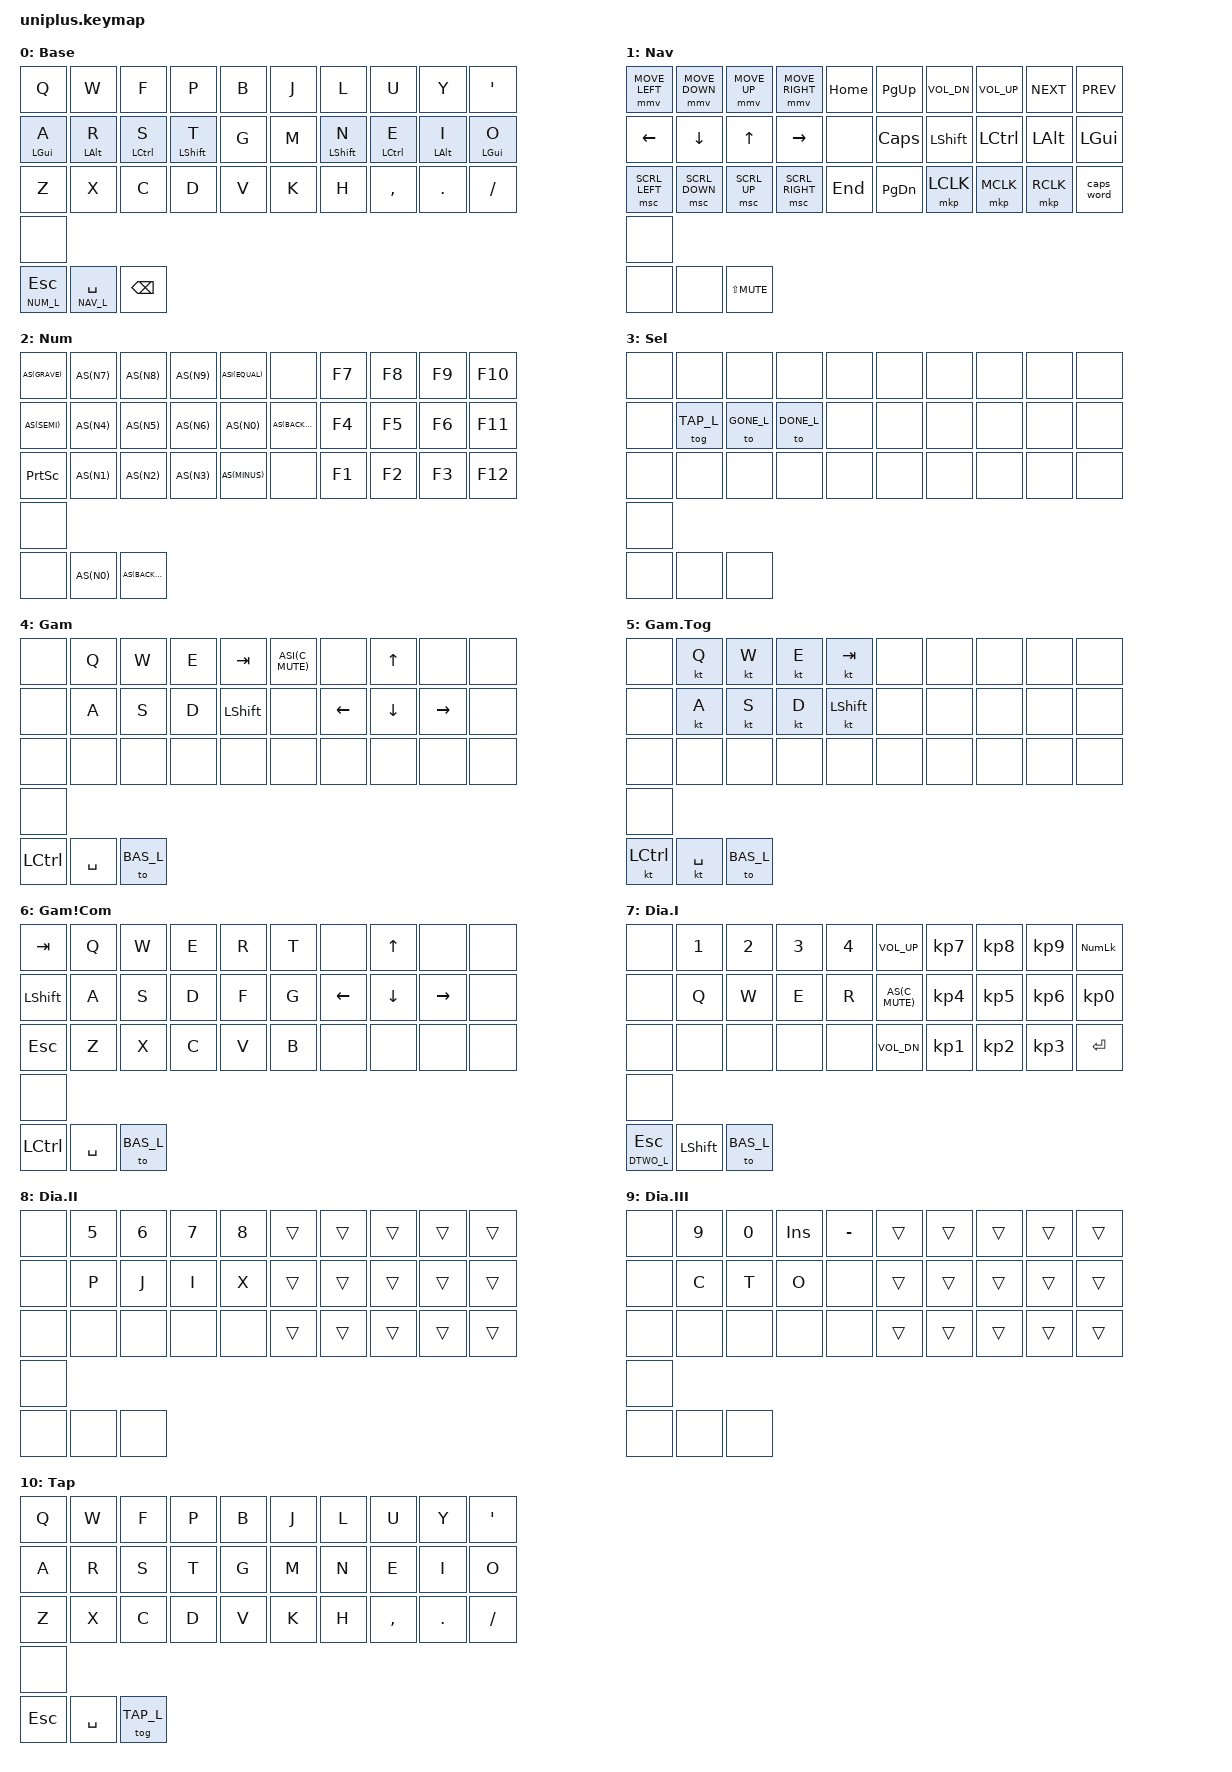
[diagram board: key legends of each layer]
/*
 * Copyright (c) 2024 Rooks
 *
 * SPDX-License-Identifier: MIT
 */

#include <behaviors.dtsi>
#include <dt-bindings/zmk/keys.h>
#include <dt-bindings/zmk/pointing.h>

// Autoshift Macro and Inversion
#define AS(keycode)  &as LS(keycode) keycode
#define ASI(keycode) &as keycode LS(keycode)

#define  BAS_L 0
#define  NAV_L 1
#define  NUM_L 2
#define  SEL_L 3
#define GONE_L 4
#define GTOG_L 5
#define GTWO_L 6
#define DONE_L 7
#define DTWO_L 8
#define DTHR_L 9
#define  TAP_L 10

/*
 *  0  1  2  3  4   5  6  7  8   9
 * 10 11 12 13 14  15 16 17 18  19
 * 20 21 22 23 24  25 26 27 28  29
 *       30 31 32  33
 */

#define KEYS_L  0  1  2  3  4   10 11 12 13 14  20 21 22 23 24
#define KEYS_R  5  6  7  8  9   15 16 17 18 19  25 26 27 28 29

#define THUMBS 30 31 32 33

// Using layer taps on thumbs, having quick tap as well helps w/ repeating space/backspace
&lt { quick-tap-ms = <200>; };

/ {
    behaviors {
        hml: hrm_left {
            compatible = "zmk,behavior-hold-tap";
            #binding-cells = <2>;
            bindings = <&kp>, <&kp>;
            flavor = "balanced";
            tapping-term-ms = <200>;
            quick-tap-ms = <150>;
            hold-trigger-key-positions = <KEYS_R THUMBS>;
            hold-trigger-on-release;
        };
        hmr: hrm_right {
            compatible = "zmk,behavior-hold-tap";
            #binding-cells = <2>;
            bindings = <&kp>, <&kp>;
            flavor = "balanced";
            tapping-term-ms = <200>;
            quick-tap-ms = <150>;
            hold-trigger-key-positions = <KEYS_L THUMBS>;
            hold-trigger-on-release;
        };
        as: auto_shift {
            compatible = "zmk,behavior-hold-tap";
            #binding-cells = <2>;
            bindings = <&kp>, <&kp>;
            flavor = "tap-preferred";
            tapping-term-ms = <200>;
            quick-tap-ms = <100>;
        };
        ght: game_hold_tap {
            compatible = "zmk,behavior-hold-tap";
            #binding-cells = <2>;
            bindings = <&kp>, <&kp>;
            flavor = "hold-preferred";
            tapping-term-ms = <150>;
        };
        glt: game_layer_tap {
            compatible = "zmk,behavior-hold-tap";
            #binding-cells = <2>;
            bindings = <&mo>, <&kp>;
            flavor = "hold-preferred";
            tapping-term-ms = <150>;
        };
    /*  Didn't work
        kt_on: key_toggle_on {
            compatible = "zmk,behavior-key-toggle";
            #binding-cells = <1>;
            display-name = "Key On";
            toggle-mode = "on";
        };
        kt_off: key_toggle_off {
            compatible = "zmk,behavior-key-toggle";
            #binding-cells = <1>;
            display-name = "Key Off";
            toggle-mode = "off";
        };
    */
    };

    keymap {
        compatible = "zmk,keymap";

        base_layer {
            display-name = "Base";
            bindings = <
                &kp Q       &kp W       &kp F        &kp P        &kp B    &kp J  &kp L        &kp U        &kp Y       &kp QUOT
                &hml LGUI A &hml LALT R &hml LCTRL S &hml LSHFT T &kp G    &kp M  &hmr LSHFT N &hmr LCTRL E &hmr LALT I &hmr LGUI O
                &kp Z       &kp X       &kp C        &kp D        &kp V    &kp K  &kp H        &kp COMMA    &kp DOT     &kp FSLH
                &none
                &lt NUM_L ESC &lt NAV_L SPACE &kp BKSP
                >;
            sensor-bindings = <&inc_dec_kp C_VOL_UP C_VOL_DN>;
        };

        navigate_layer {
            display-name = "Nav";
            bindings = <
                &mmv MOVE_LEFT &mmv MOVE_DOWN &mmv MOVE_UP &mmv MOVE_RIGHT &kp HOME    &kp PG_UP &kp C_VOL_DN &kp C_VOL_UP &kp C_NEXT &kp C_PREV
                &kp  LEFT      &kp  DOWN      &kp  UP      &kp  RIGHT      &none       &kp CAPS  &kp LSHFT    &kp LCTRL    &kp LALT   &kp LGUI
                &msc SCRL_LEFT &msc SCRL_DOWN &msc SCRL_UP &msc SCRL_RIGHT &kp END     &kp PG_DN &mkp LCLK    &mkp MCLK    &mkp RCLK  &caps_word
                &none
                &none &none &kp LS(C_MUTE)
                >;
            sensor-bindings = <&inc_dec_kp C_VOL_UP C_VOL_DN>;
        };

        number_layer {
            display-name = "Num";
            bindings = <
                AS(GRAVE) AS(N7) AS(N8) AS(N9) ASI(EQUAL)    &none         &kp F7 &kp F8 &kp F9 &kp F10
                AS(SEMI)  AS(N4) AS(N5) AS(N6) AS(N0)        AS(BACKSLASH) &kp F4 &kp F5 &kp F6 &kp F11
                &kp PSCRN AS(N1) AS(N2) AS(N3) AS(MINUS)     &none         &kp F1 &kp F2 &kp F3 &kp F12
                &none
                &none AS(N0) AS(BACKSLASH)
                >;
            sensor-bindings = <&inc_dec_kp C_VOL_UP C_VOL_DN>;
        };

        layer_selection_layer {
            display-name = "Sel";
            bindings = <
                &none &none      &none      &none      &none     &none &none &none &none &none
                &none &tog TAP_L &to GONE_L &to DONE_L &none     &none &none &none &none &none
                &none &none      &none      &none      &none     &none &none &none &none &none
                &none
                &none &none &none
                >;
            sensor-bindings = <&inc_dec_kp C_VOL_UP C_VOL_DN>;
        };

        gaming_layer {
            display-name = "Gam";
            bindings = <
                &none &kp Q &kp W &kp E &kp TAB      ASI(C_MUTE) &none    &kp UP   &none     &none
                &none &kp A &kp S &kp D &kp LSHFT    &none       &kp LEFT &kp DOWN &kp RIGHT &none
                &none &none &none &none &none        &none       &none    &none    &none     &none
                &none
                &kp LCTL  &kp SPACE &to BAS_L
                >;
            sensor-bindings = <&inc_dec_kp C_VOL_UP C_VOL_DN>;
        };

        gaming_toggles_layer {
            display-name = "Gam.Tog";
            bindings = <
                &none &kt Q &kt W &kt E &kt TAB      &none &none &none &none &none
                &none &kt A &kt S &kt D &kt LSHFT    &none &none &none &none &none
                &none &none &none &none &none        &none &none &none &none &none
                &none
                &kt LCTL  &kt SPACE &to BAS_L
                >;
            sensor-bindings = <&inc_dec_kp C_VOL_UP C_VOL_DN>;
        };

        gaming_noncomb_layer {
            display-name = "Gam!Com";
            bindings = <
                &kp TAB    &kp Q &kp W &kp E &kp R    &kp T &none    &kp UP   &none     &none
                &kp LSHIFT &kp A &kp S &kp D &kp F    &kp G &kp LEFT &kp DOWN &kp RIGHT &none
                &kp ESC    &kp Z &kp X &kp C &kp V    &kp B &none    &none    &none     &none
                &none
                &kp LCTL &kp SPACE &to BAS_L
                >;
        };

        diablo_layer {
            display-name = "Dia.I";
            bindings = <
                &none &kp N1 &kp N2 &kp N3 &kp N4    &kp C_VOL_UP &kp KP_N7 &kp KP_N8 &kp KP_N9 &kp KP_NUM
                &none &kp Q  &kp W  &kp E  &kp R      AS(C_MUTE)  &kp KP_N4 &kp KP_N5 &kp KP_N6 &kp KP_N0
                &none &none  &none  &none  &none     &kp C_VOL_DN &kp KP_N1 &kp KP_N2 &kp KP_N3 &kp RET
                &none
                &lt DTWO_L ESC &kp LSHFT &to BAS_L
                >;
            sensor-bindings = <&inc_dec_kp C_VOL_UP C_VOL_DN>;
            // IWC
        };

        diablo_two_layer {
            display-name = "Dia.II";
            bindings = <
                &none &kp N5 &kp N6 &kp N7 &kp N8    &trans &trans &trans &trans &trans
                &none &kp P  &kp J  &kp I  &kp X     &trans &trans &trans &trans &trans
                &none &none  &none  &none  &none     &trans &trans &trans &trans &trans
                &none
                &none &none &none
                >;
            sensor-bindings = <&inc_dec_kp C_VOL_UP C_VOL_DN>;
        };

        diablo_three_layer {
            display-name = "Dia.III";
            bindings = <
                &none &kp N9 &kp N0 &kp INS &kp MINUS    &trans &trans &trans &trans &trans
                &none &kp C  &kp T  &kp O   &none        &trans &trans &trans &trans &trans
                &none &none  &none  &none   &none        &trans &trans &trans &trans &trans
                &none
                &none &none &none
                >;
            sensor-bindings = <&inc_dec_kp C_VOL_UP C_VOL_DN>;
        };

        tap_layer {
            display-name = "Tap";
            bindings = <
                &kp Q &kp W &kp F &kp P &kp B    &kp J &kp L &kp U     &kp Y   &kp QUOT
                &kp A &kp R &kp S &kp T &kp G    &kp M &kp N &kp E     &kp I   &kp O
                &kp Z &kp X &kp C &kp D &kp V    &kp K &kp H &kp COMMA &kp DOT &kp FSLH
                &none
                &kp ESC &kp SPACE &tog TAP_L
                >;
            sensor-bindings = <&inc_dec_kp C_VOL_UP C_VOL_DN>;
        };

    };

    /*  Didn't work
    macros {
        fkp: force_key_press {
            compatible = "zmk,behavior-macro-one-param";
            #binding-cells = <1>;
            bindings
                = <&macro_param_1to1>
                , <&macro_press &kp  MACRO_PLACEHOLDER>
                , <&macro_pause_for_release>
                , <&macro_param_1to1>
                , <&macro_release &kp MACRO_PLACEHOLDER>;
        };
        tap_longer: tap_longer {
            compatible = "zmk,behavior-macro-one-param";
            #binding-cells = <1>;
            bindings
                = <&macro_param_1to1>
                , <&macro_tap &kp MACRO_PLACEHOLDER>;
        };
    };
    */

    combos {
        compatible = "zmk,combos";
        combo_boot       { timeout-ms = <50>; key-positions = <0 9 20 29>; bindings = <&bootloader>; };

        combo_ret        { timeout-ms = <50>; key-positions = <25 33>; bindings = <&kp RET>;    layers = <BAS_L>;  };
        combo_del        { timeout-ms = <50>; key-positions = <16 18>; bindings = <&kp DEL>;    layers = <BAS_L>;  };
        combo_tab        { timeout-ms = <50>; key-positions = <11 13>; bindings = <&kp TAB>;    layers = <BAS_L>;  };

        combo_angle_l    { timeout-ms = <50>; key-positions = <10 20>; bindings = <&kp LT>;     layers = <BAS_L>;  };
        combo_brace_l    { timeout-ms = <50>; key-positions = <11 21>; bindings = <&kp LBRC>;   layers = <BAS_L>;  };
        combo_bracket_l  { timeout-ms = <50>; key-positions = <12 22>; bindings = <&kp LBKT>;   layers = <BAS_L>;  };
        combo_paren_l    { timeout-ms = <50>; key-positions = <13 23>; bindings = <&kp LPAR>;   layers = <BAS_L>;  };
        combo_paren_r    { timeout-ms = <50>; key-positions = <16 26>; bindings = <&kp RPAR>;   layers = <BAS_L>;  };
        combo_bracket_r  { timeout-ms = <50>; key-positions = <17 27>; bindings = <&kp RBKT>;   layers = <BAS_L>;  };
        combo_brace_r    { timeout-ms = <50>; key-positions = <18 28>; bindings = <&kp RBRC>;   layers = <BAS_L>;  };
        combo_angle_r    { timeout-ms = <50>; key-positions = <19 29>; bindings = <&kp GT>;     layers = <BAS_L>;  };
        combo_select     { timeout-ms = <50>; key-positions = <31 32>; bindings = <&mo SEL_L>;  layers = <BAS_L>;  };

        combo_mute       { timeout-ms = <50>; key-positions = <6 7>;   bindings = <&kp C_MUTE>; layers = <NAV_L>;  };
        combo_pp         { timeout-ms = <50>; key-positions = <8 9>;   bindings = <&kp C_PP>;   layers = <NAV_L>;  };

        combo_game_esc   { timeout-ms = <50>; key-positions = <3 4>;   bindings = <&kp ESC>;    layers = <GONE_L>; };
        combo_game_b     { timeout-ms = <50>; key-positions = <1 3>;   bindings = <&kp B>;      layers = <GONE_L>; };
        combo_game_g     { timeout-ms = <50>; key-positions = <1 2>;   bindings = <&kp G>;      layers = <GONE_L>; };
        combo_game_r     { timeout-ms = <50>; key-positions = <2 3>;   bindings = <&kp R>;      layers = <GONE_L>; };
        combo_game_f     { timeout-ms = <50>; key-positions = <3 13>;  bindings = <&kp F>;      layers = <GONE_L>; };
        combo_game_v     { timeout-ms = <50>; key-positions = <2 13>;  bindings = <&kp V>;      layers = <GONE_L>; };
        combo_game_z     { timeout-ms = <50>; key-positions = <11 12>; bindings = <&kp Z>;      layers = <GONE_L>; };
        combo_game_x     { timeout-ms = <50>; key-positions = <12 13>; bindings = <&kp X>;      layers = <GONE_L>; };
        combo_game_c     { timeout-ms = <50>; key-positions = <23 31>; bindings = <&kp C>;      layers = <GONE_L>; };
        combo_game_la    { timeout-ms = <50>; key-positions = <24 32>; bindings = <&kp LALT>;   layers = <GONE_L>; };

        combo_game_tg_b  { timeout-ms = <50>; key-positions = <1 3>;   bindings = <&kt B>;      layers = <GTOG_L>; };
        combo_game_tg_g  { timeout-ms = <50>; key-positions = <1 2>;   bindings = <&kt G>;      layers = <GTOG_L>; };
        combo_game_tg_r  { timeout-ms = <50>; key-positions = <2 3>;   bindings = <&kt R>;      layers = <GTOG_L>; };
        combo_game_tg_f  { timeout-ms = <50>; key-positions = <3 13>;  bindings = <&kt F>;      layers = <GTOG_L>; };
        combo_game_tg_v  { timeout-ms = <50>; key-positions = <2 13>;  bindings = <&kt V>;      layers = <GTOG_L>; };
        combo_game_tg_z  { timeout-ms = <50>; key-positions = <11 12>; bindings = <&kt Z>;      layers = <GTOG_L>; };
        combo_game_tg_x  { timeout-ms = <50>; key-positions = <12 13>; bindings = <&kt X>;      layers = <GTOG_L>; };
        combo_game_tg_c  { timeout-ms = <50>; key-positions = <23 31>; bindings = <&kt C>;      layers = <GTOG_L>; };
        combo_game_tg_la { timeout-ms = <50>; key-positions = <24 32>; bindings = <&kt LALT>;   layers = <GTOG_L>; };

        combo_game_sl_tg { timeout-ms = <50>; key-positions = <11 13>; bindings = <&sl GTOG_L>; layers = <GONE_L>; };
        combo_decombo    { timeout-ms = <50>; key-positions = <9 29>;  bindings = <&to GTWO_L>; layers = <GONE_L>; };
        combo_recombo    { timeout-ms = <50>; key-positions = <9 29>;  bindings = <&to GONE_L>; layers = <GTWO_L>; };

        combo_d2_lc      { timeout-ms = <50>; key-positions = <23 31>; bindings = <&kp LCTRL>;     layers = <DONE_L>; };
        combo_d2_grave   { timeout-ms = <50>; key-positions = <3 4>;   bindings = <&kp GRAVE>;     layers = <DONE_L>; };
        combo_d2_lt_3_z  { timeout-ms = <50>; key-positions = <24 32>; bindings = <&glt DTHR_L Z>; layers = <DONE_L>; };

        combo_sl_tap     { timeout-ms = <50>; key-positions = <26 33>; bindings = <&sl TAP_L>;     layers = <BAS_L GONE_L DONE_L>; };
    };

/*
 *  0  1  2  3  4   5  6  7  8  9
 * 10 11 12 13 14  15 16 17 18 19
 * 20 21 22 23 24  25 26 27 28 29
 *       30 31 32  33
 */

};

// vim: ft=c
